# alb32r003x register map
Vendor: ALB; Series: ALB RT SoC
CPU: ALB XF, little endian
Registers are 32-bit, access not given, reset 0x0 unless marked. A register's access mark holds for its fields unless they carry their own. Offsets are from the block's base; [hi:lo] are bit positions.

## SCI1
Base 0x28000000
Same registers: SCI2 0x28001000
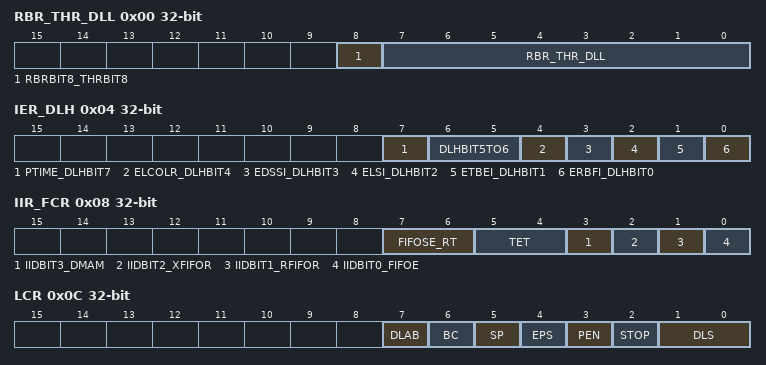
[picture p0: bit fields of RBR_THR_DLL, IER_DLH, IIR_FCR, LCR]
0x00 RBR_THR_DLL
  [8] RBRBIT8_THRBIT8 — bit8 of Receive Buffer, Transmit Holding.
  [7:0] RBR_THR_DLL — bit0-7 of Receive Buffer, Transmit Holding, Divisor Latch (Low).
0x04 IER_DLH
  [7] PTIME_DLHBIT7 — Programmable THRE Interrupt Mode Enable register, bit7 of register Divisor Latch (High).
  [6:5] DLHBIT5TO6 — bit5-6 of register Divisor Latch (High).
  [4] ELCOLR_DLHBIT4 — Interrupt Enable Register, bit4 of register Divisor Latch (High).
  [3] EDSSI_DLHBIT3 — Enable Modem Status Interrupt register, bit3 of register Divisor Latch (High).
  [2] ELSI_DLHBIT2 — Enable Receiver Line Status Interrupt register, bit2 of register Divisor Latch (High).
  [1] ETBEI_DLHBIT1 — Enable Transmit Holding Register Empty Interrupt register, bit1 of register Divisor Latch (High).
  [0] ERBFI_DLHBIT0 — Enable Received Data Available Interrupt register, bit0 of register Divisor Latch (High).
0x08 IIR_FCR
  [7:6] FIFOSE_RT
  [5:4] TET — TX Empty Trigger (or TET) register.
  [3] IIDBIT3_DMAM — Bit3 of Interrupt ID (or IID) register, DMA Mode (or DMAM) register.
  [2] IIDBIT2_XFIFOR — Bit3 of Interrupt ID (or IID) register, XMIT FIFO Reset (or XFIFOR) register.
  [1] IIDBIT1_RFIFOR — Bit3 of Interrupt ID (or IID) register, RCVR FIFO Reset (or RFIFOR) register.
  [0] IIDBIT0_FIFOE — Bit3 of Interrupt ID (or IID) register, FIFO Enable (or FIFOE) register.
0x0C LCR
  [7] DLAB — Divisor Latch Access Bit.
  [6] BC — Break Control Bit.
  [5] SP — Stick Parity.
  [4] EPS — Even Parity Select.
  [3] PEN — Parity Enable.
  [2] STOP — Number of stop bits.
  [1:0] DLS — Data Length Select (or CLS as used in legacy).
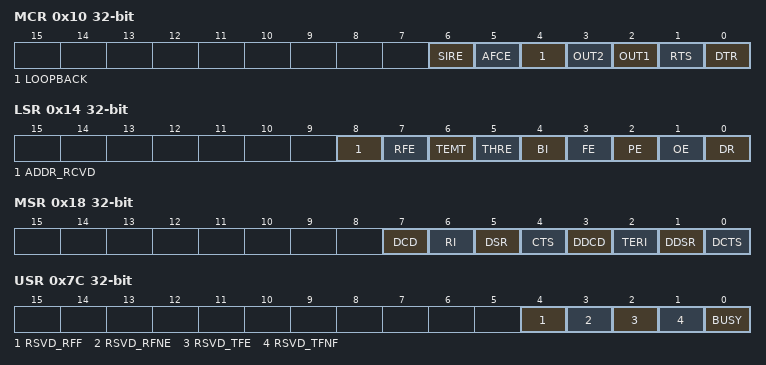
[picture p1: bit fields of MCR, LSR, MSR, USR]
0x10 MCR
  [6] SIRE — SIR Mode Enable
  [5] AFCE — Auto Flow Control Enable
  [4] LOOPBACK — LoopBack Bit
  [3] OUT2
  [2] OUT1
  [1] RTS — Request to Send.
  [0] DTR — Data Terminal Ready.
0x14 LSR
  [8] ADDR_RCVD — Address Received Bit.
  [7] RFE — Receiver FIFO Error bit.
  [6] TEMT — Transmitter Empty bit.
  [5] THRE — Transmit Holding Register Empty bit.
  [4] BI — Break Interrupt bit.
  [3] FE — Framing Error bit.
  [2] PE — Parity Error bit.
  [1] OE — Overrun error bit.
  [0] DR — Data Ready bit.
0x18 MSR
  [7] DCD — Data Carrier Detect.
  [6] RI — Ring Indicator.
  [5] DSR — Data Set Ready.
  [4] CTS — Clear to Send.
  [3] DDCD — Delta Data Carrier Detect.
  [2] TERI — Trailing Edge of Ring Indicator.
  [1] DDSR — Delta Data Set Ready.
  [0] DCTS — Delta Clear to Send.
0x1C SCR
  [7:0] SCR — This register is for programmers to use as a temporary storage space. It has no defined purpose in the
0x20 LPDLL
  [7:0] LPDLL — This register makes up the lower 8-bits of a 16-bit, read/write, Low Power Divisor Latch register that
0x24 LPDLH
  [7:0] LPDLH — This register makes up the upper 8-bits of a 16-bit, read/write, Low Power Divisor Latch register that
0x70 FAR
  [0] FAR — Writes will have no effect when FIFO_ACCESS == No, always readable. This register is use to enable a
0x7C USR
  [4] RSVD_RFF — Receive FIFO Full.
  [3] RSVD_RFNE — Receive FIFO Not Empty.
  [2] RSVD_TFE — Transmit FIFO Empty.
  [1] RSVD_TFNF — Transmit FIFO Not Full.
  [0] BUSY — UART Busy.
0x80 TFL
  [4:0] TFL — Transmit FIFO Level.
0x84 RFL
  [4:0] RFL — Receive FIFO Level.
0xA4 HTX
  [0] HTX — Halt TX.
0xA8 DMASA
  [0] DMASA — DMA Software Acknowledge.
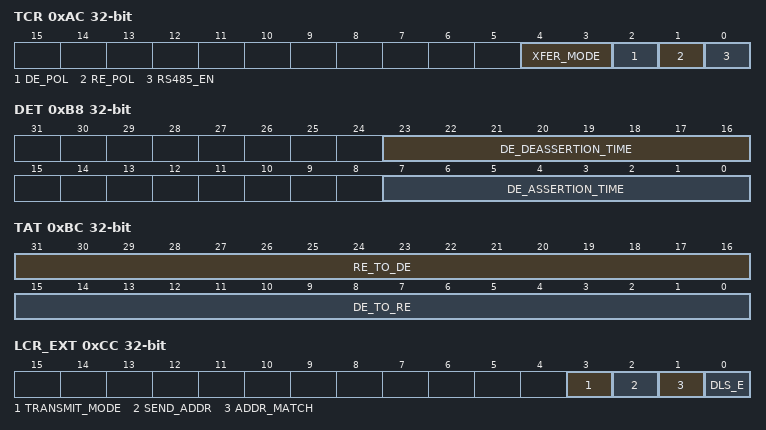
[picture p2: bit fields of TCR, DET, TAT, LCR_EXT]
0xAC TCR
  [4:3] XFER_MODE — Transfer Mode.
  [2] DE_POL — Driver Enable Polarity.
  [1] RE_POL — Receiver Enable Polarity.
  [0] RS485_EN — RS485 Transfer Enable.
0xB0 DE_EN
  [0] DE_ENABLE — DE Enable control.
0xB4 RE_EN
  [0] RE_ENABLE — RE Enable control.
0xB8 DET
  [23:16] DE_DEASSERTION_TIME — Driver Enable de-assertion time.
  [7:0] DE_ASSERTION_TIME — Driver Enable assertion time.
0xBC TAT
  [31:16] RE_TO_DE — Receiver Enable to Driver Enable TurnAround time.
  [15:0] DE_TO_RE — Driver Enable to Receiver Enable TurnAround time.
0xC4 RAR
  [7:0] RAR — This is an address matching register during receive mode. If the 9-th bit is set in the incoming character
0xC8 TAR
  [7:0] TAR — This is an address matching register during transmit mode. If DLS_E (LCR_EXT[0]) bit is enabled, then
0xCC LCR_EXT
  [3] TRANSMIT_MODE — Transmit mode control bit. This bit is used to control the type of transmit mode during 9-bit data transfers.
  [2] SEND_ADDR — Send address control bit. This bit is used as a control knob for the user to determine when to send the
  [1] ADDR_MATCH — Address Match Mode.This bit is used to enable the address match feature during receive.
  [0] DLS_E — Extension for DLS. This bit is used to enable 9-bit data for transmit and receive transfers.
